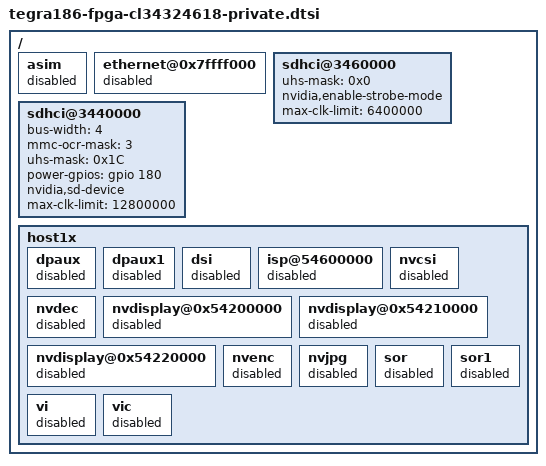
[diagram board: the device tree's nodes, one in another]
/*
 * arch/arm64/boot/dts/tegra186-fpga-cl34324618-private.dtsi
 *
 * Copyright (c) 2015, NVIDIA CORPORATION.  All rights reserved.
 *
 * This program is free software; you can redistribute it and/or modify
 * it under the terms of the GNU General Public License as published by
 * the Free Software Foundation; version 2 of the License.
 *
 * This program is distributed in the hope that it will be useful, but WITHOUT
 * ANY WARRANTY; without even the implied warranty of MERCHANTABILITY or
 * FITNESS FOR A PARTICULAR PURPOSE.  See the GNU General Public License for
 * more details.
 *
 * You should have received a copy of the GNU General Public License along
 * with this program; if not, write to the Free Software Foundation, Inc.,
 * 51 Franklin Street, Fifth Floor, Boston, MA  02110-1301, USA.
 *
 */

/ {
	asim {
		status = "disabled";
	};

	ethernet@0x7ffff000 {
		status = "disabled";
	};

	sdhci@3460000 {
		uhs-mask = <0x0>;
		nvidia,enable-strobe-mode;
		max-clk-limit = <6400000>;
		status = "okay";
        };

	sdhci@3440000 {
		bus-width = <4>;
		mmc-ocr-mask = <3>;
		uhs-mask = <0x1C>;
		power-gpios = <&gpio 180 0>;
		nvidia,sd-device;
		max-clk-limit = <12800000>;
		status = "okay";
        };

	host1x: host1x {
		dpaux {
			status = "disabled";
		};

		dpaux1 {
			status = "disabled";
		};

		dsi {
			status = "disabled";
		};

		isp@54600000 {
			status = "disabled";
		};

		nvcsi {
			status = "disabled";
		};

		nvdec {
			status = "disabled";
		};

		nvdisplay@0x54200000 {
			status = "disabled";
		};

		nvdisplay@0x54210000 {
			status = "disabled";
		};

		nvdisplay@0x54220000 {
			status = "disabled";
		};

		nvenc {
			status = "disabled";
		};

		nvjpg {
			status = "disabled";
		};

		sor {
			status = "disabled";
		};

		sor1 {
			status = "disabled";
		};

		vi {
			status = "disabled";
		};

		vic {
			status = "disabled";
		};
	};
};
